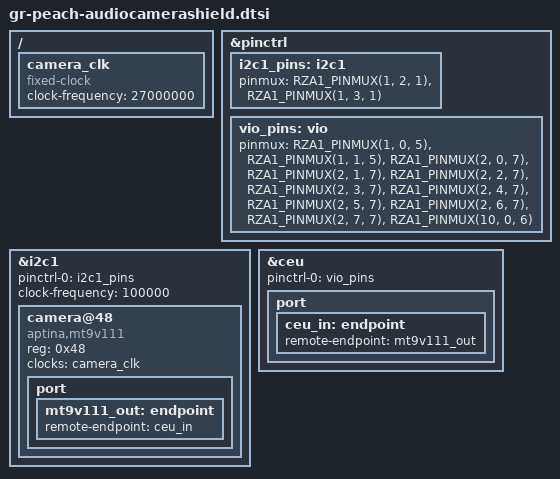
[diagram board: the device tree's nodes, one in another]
#include "r7s72100.dtsi"
#include <dt-bindings/gpio/gpio.h>
#include <dt-bindings/pinctrl/r7s72100-pinctrl.h>
/ {
	camera_clk: camera_clk {
		compatible = "fixed-clock";
		#clock-cells = <0>;
		clock-frequency = <27000000>;
	};
};
&pinctrl {
	i2c1_pins: i2c1 {
		pinmux = <RZA1_PINMUX(1, 2, 1)>, <RZA1_PINMUX(1, 3, 1)>;
	};
	vio_pins: vio {
		pinmux = <RZA1_PINMUX(1, 0, 5)>,  
			 <RZA1_PINMUX(1, 1, 5)>,  
			 <RZA1_PINMUX(2, 0, 7)>,  
			 <RZA1_PINMUX(2, 1, 7)>,  
			 <RZA1_PINMUX(2, 2, 7)>,  
			 <RZA1_PINMUX(2, 3, 7)>,  
			 <RZA1_PINMUX(2, 4, 7)>,  
			 <RZA1_PINMUX(2, 5, 7)>,  
			 <RZA1_PINMUX(2, 6, 7)>,  
			 <RZA1_PINMUX(2, 7, 7)>,  
			 <RZA1_PINMUX(10, 0, 6)>;  
	};
};
&i2c1 {
	pinctrl-names = "default";
	pinctrl-0 = <&i2c1_pins>;
	status = "okay";
	clock-frequency = <100000>;
	camera@48 {
		compatible = "aptina,mt9v111";
		reg = <0x48>;
		clocks = <&camera_clk>;
		port {
			mt9v111_out: endpoint {
				remote-endpoint = <&ceu_in>;
			};
		};
	};
};
&ceu {
	pinctrl-names = "default";
	pinctrl-0 = <&vio_pins>;
	status = "okay";
	port {
		ceu_in: endpoint {
			remote-endpoint = <&mt9v111_out>;
		};
	};
};
